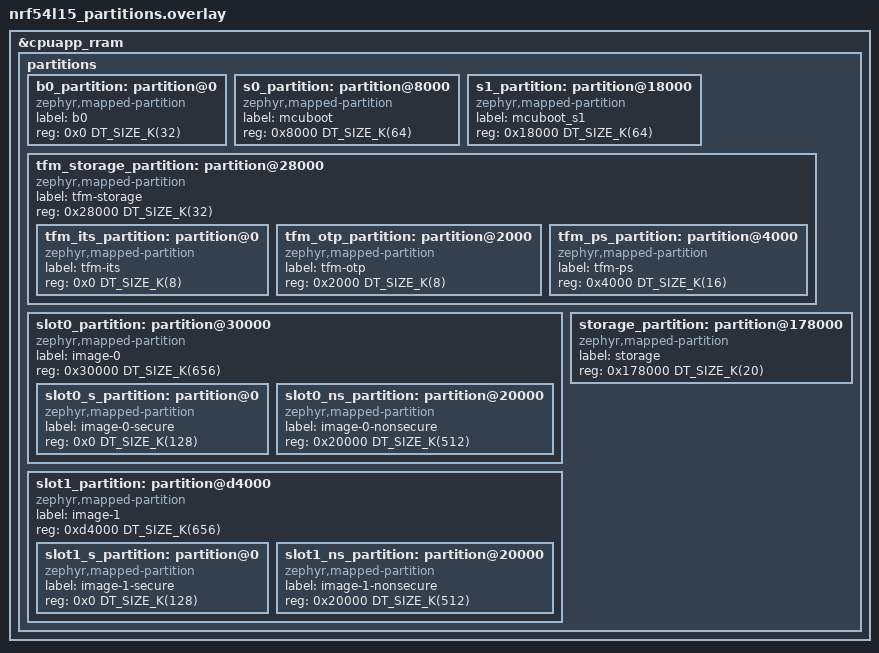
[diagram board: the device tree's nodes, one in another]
/*
 * Copyright (c) 2026 Nordic Semiconductor ASA
 *
 * SPDX-License-Identifier: LicenseRef-Nordic-5-Clause
 */


&cpuapp_rram {
	partitions {
		ranges;
		#address-cells = <1>;
		#size-cells = <1>;

		b0_partition: partition@0 {
			compatible = "zephyr,mapped-partition";
			label = "b0";
			reg = <0x0 DT_SIZE_K(32)>;
		};

		s0_partition: partition@8000 {
			compatible = "zephyr,mapped-partition";
			label = "mcuboot";
			reg = <0x8000 DT_SIZE_K(64)>;
		};

		s1_partition: partition@18000 {
			compatible = "zephyr,mapped-partition";
			label = "mcuboot_s1";
			reg = <0x18000 DT_SIZE_K(64)>;
		};

		tfm_storage_partition: partition@28000 {
			compatible = "zephyr,mapped-partition";
			label = "tfm-storage";
			reg = <0x28000 DT_SIZE_K(32)>;
			ranges = <0x0 0x28000 DT_SIZE_K(32)>;
			#address-cells = <1>;
			#size-cells = <1>;

			tfm_its_partition: partition@0 {
				compatible = "zephyr,mapped-partition";
				label = "tfm-its";
				reg = <0x0 DT_SIZE_K(8)>;
			};

			tfm_otp_partition: partition@2000 {
				compatible = "zephyr,mapped-partition";
				label = "tfm-otp";
				reg = <0x2000 DT_SIZE_K(8)>;
			};

			tfm_ps_partition: partition@4000 {
				compatible = "zephyr,mapped-partition";
				label = "tfm-ps";
				reg = <0x4000 DT_SIZE_K(16)>;
			};
		};

		slot0_partition: partition@30000 {
			compatible = "zephyr,mapped-partition";
			label = "image-0";
			reg = <0x30000 DT_SIZE_K(656)>;
			ranges = <0x0 0x30000 DT_SIZE_K(656)>;
			#address-cells = <1>;
			#size-cells = <1>;

			slot0_s_partition: partition@0 {
				compatible = "zephyr,mapped-partition";
				label = "image-0-secure";
				reg = <0x0 DT_SIZE_K(128)>;
			};

			slot0_ns_partition: partition@20000 {
				compatible = "zephyr,mapped-partition";
				label = "image-0-nonsecure";
				reg = <0x20000 DT_SIZE_K(512)>;
			};
		};

		slot1_partition: partition@d4000 {
			compatible = "zephyr,mapped-partition";
			label = "image-1";
			reg = <0xd4000 DT_SIZE_K(656)>;
			ranges = <0x0 0xd4000 DT_SIZE_K(656)>;
			#address-cells = <1>;
			#size-cells = <1>;

			slot1_s_partition: partition@0 {
				compatible = "zephyr,mapped-partition";
				label = "image-1-secure";
				reg = <0x0 DT_SIZE_K(128)>;
			};

			slot1_ns_partition: partition@20000 {
				compatible = "zephyr,mapped-partition";
				label = "image-1-nonsecure";
				reg = <0x20000 DT_SIZE_K(512)>;
			};
		};
		
		storage_partition: partition@178000 {
			compatible = "zephyr,mapped-partition";
			label = "storage";
			reg = <0x178000 DT_SIZE_K(20)>;
		};
	};
};
